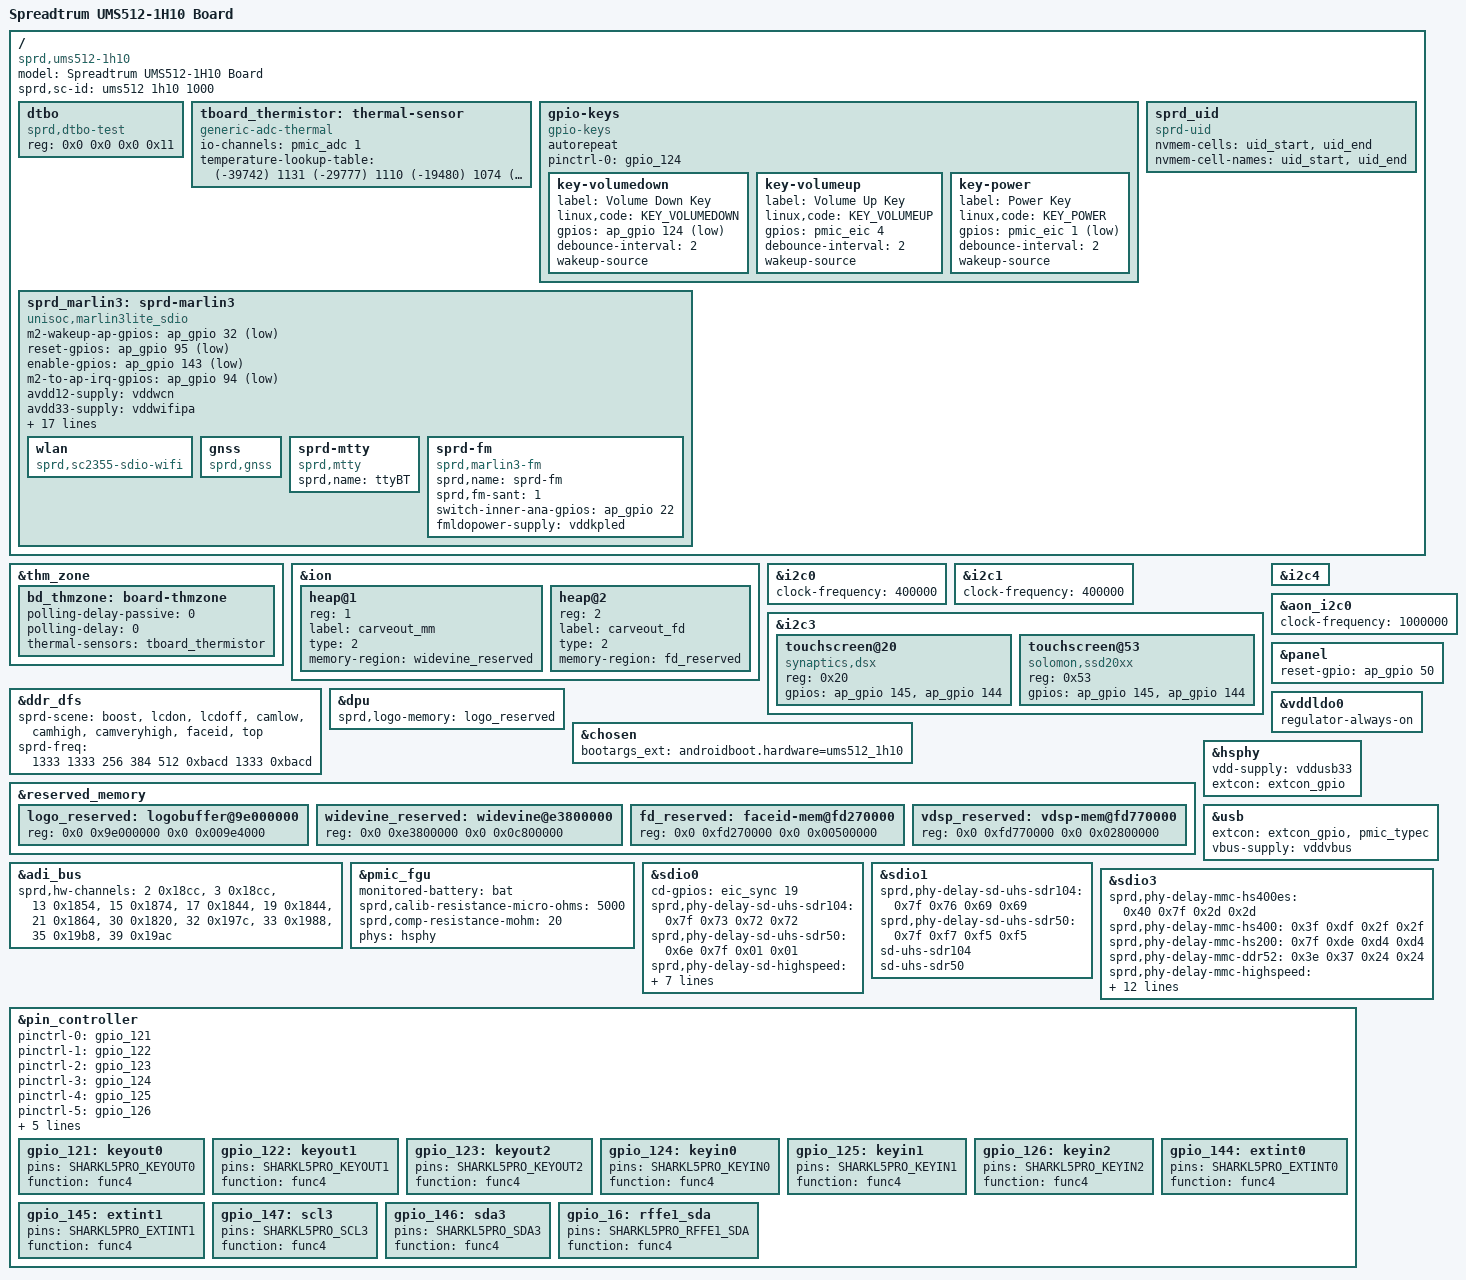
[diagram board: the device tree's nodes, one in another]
/dts-v1/;
/plugin/;

#include <dt-bindings/clock/sprd,ums512-clk.h>
#include <dt-bindings/input/input.h>
#include <dt-bindings/gpio/gpio.h>
#include <dt-bindings/mfd/sprd,sc2730-regs.h>
#include <dt-bindings/mfd/sprd,sc2730-mask.h>



/ {
	model = "Spreadtrum UMS512-1H10 Board";

	compatible = "sprd,ums512-1h10", "sprd,ums512";

	sprd,sc-id = "ums512 1h10 1000";

	fragment {
		target-path = "/";
		__overlay__ {
			#address-cells = <2>;
			#size-cells = <2>;

			dtbo: dtbo {
				compatible = "sprd,dtbo-test";
				reg = <0x0 0x0 0x0 0x11>;
			};
			/*
			pwm_backlight: sprd_backlight {
				compatible = "sprd,sharkl5pro-backlight";
				pwms = <&pwms 2 40000>;
				pwm-names = "backlight";
				sprd,max-brightness-level = <880>;
				default-brightness-level = <250>;
				sprd,brightness-scale = <1023>;
				brightness-levels = <
							  0   3   4   5   6   7
					  8   9  10  11  12  13  14  15  16  17
					 18  19  20  21  22  23  24  25  26  27
					 28  29  31  33  35  37  39  41  43  45
					 46  48  50  52  54  56  58  60  62  64
					 66  68  70  72  74  76  78  80  82  84
					 86  88  90  92  94  96  98 100 102 104
					106 108 110 112 114 116 118 120 122 124
					126 128 130 132 134 136 138 140 142 144
					146 148 150 152 154 156 158 160 162 164
					166 169 172 175 178 181 184 187 190 193
					196 199 202 205 208 211 214 217 220 223
					226 229 232 235 238 241 244 247 250 253
					256 259 262 265 268 271 274 277 280 283
					286 290 294 298 302 306 310 314 318 322
					326 330 334 338 342 346 350 354 358 362
					366 370 374 378 382 386 390 394 398 402
					406 410 414 418 422 426 430 434 438 442
					446 451 456 461 466 471 476 481 486 491
					496 501 506 511 516 521 526 531 536 541
					546 551 556 561 566 571 576 581 586 591
					596 601 606 611 616 621 626 631 636 641
					646 652 658 664 670 676 682 688 694 700
					706 712 718 724 730 736 742 748 754 760
					766 772 778 784 790 796 802 808 814 820
					826 832 838 844 850 856 862 868 874 880
					>;
			};*/


			tboard_thermistor:thermal-sensor {
				compatible = "generic-adc-thermal";
				#thermal-sensor-cells = <0>;
				io-channels = <&pmic_adc 1>;
				io-channel-names = "sensor-channel";
				temperature-lookup-table = <    (-39742) 1131
								(-29777) 1110
								(-19480) 1074
								(-4679) 983
								10110 838
								24805 654
								44922 413
								54903 316
								64895 238
								74884 178
								84883 133
								94883 100
								104880 75
								114889 57
								124872 43 >;
			};
			gpio-keys {
				compatible = "gpio-keys";
				autorepeat;
				pinctrl-names = "gpio_124";
				pinctrl-0 = <&gpio_124>;
				key-volumedown {
					label = "Volume Down Key";
					linux,code = <KEY_VOLUMEDOWN>;
					gpios = <&ap_gpio 124 GPIO_ACTIVE_LOW>;
					debounce-interval = <2>;
					wakeup-source;
				};

				key-volumeup {
					label = "Volume Up Key";
					linux,code = <KEY_VOLUMEUP>;
					gpios = <&pmic_eic 4 GPIO_ACTIVE_HIGH>;
					debounce-interval = <2>;
					wakeup-source;
				};

				key-power {
					label = "Power Key";
					linux,code = <KEY_POWER>;
					gpios = <&pmic_eic 1 GPIO_ACTIVE_LOW>;
					debounce-interval = <2>;
					wakeup-source;
				};
			};

			sprd_uid {
				compatible = "sprd-uid";
				nvmem-cells = <&uid_start>, <&uid_end>;
				nvmem-cell-names = "uid_start", "uid_end";
			};

			sprd_marlin3: sprd-marlin3 {
				compatible = "unisoc,marlin3lite_sdio";
				m2-wakeup-ap-gpios = <&ap_gpio 32 GPIO_ACTIVE_LOW>;
				reset-gpios = <&ap_gpio 95 GPIO_ACTIVE_LOW>;
				enable-gpios = <&ap_gpio 143 GPIO_ACTIVE_LOW>;
				m2-to-ap-irq-gpios = <&ap_gpio 94 GPIO_ACTIVE_LOW>;
				avdd12-supply = <&vddwcn>;
				avdd33-supply = <&vddwifipa>;
				dcxo18-supply = <&vddsim2>;

				clock-names = "clk_32k","source","enable";
				clocks = <&aon_clk CLK_AUX0>,
					 <&ext_32k>,
					 <&aonapb_gate CLK_AUX0_EB>;

				extcon = <&sdio1>;
				sdhci-name = <&sdio1>;

				sprd,btwf-file-name = "/dev/block/platform/soc/soc:ap-apb/71400000.sdio/by-name/wcnmodem";
				sprd,gnss-file-name = "/vendor/firmware/gnssmodem.bin";
				adma-tx;
				adma-rx;
				/*
				 * bound parameter:
				 * [0]:addr offset, [1]:mask, [2]:unboundval, [3]:boundval
				 */
				avdd12-parent-bound-chip = <REG_ANA_SLP_DCDC_PD_CTRL MASK_ANA_SLP_DCDCGEN1_PD_EN 0x0 MASK_ANA_SLP_DCDCGEN1_PD_EN>;
				avdd12-bound-wbreq = <REG_ANA_LDO_XTL_EN10 MASK_ANA_LDO_VDDWCN_EXT_XTL3_EN 0x0 MASK_ANA_LDO_VDDWCN_EXT_XTL3_EN>;
				avdd33-bound-wbreq = <REG_ANA_LDO_XTL_EN11 MASK_ANA_LDO_VDDWIFIPA_EXT_XTL3_EN 0x0 MASK_ANA_LDO_VDDWIFIPA_EXT_XTL3_EN>;

				wlan {
					compatible = "sprd,sc2355-sdio-wifi";
				};

				gnss {
					compatible = "sprd,gnss";
				};

				sprd-mtty {
					compatible = "sprd,mtty";
					sprd,name = "ttyBT";
				};

				sprd-fm {
					compatible = "sprd,marlin3-fm";
					sprd,name = "sprd-fm";
					sprd,fm-sant = <1>;
					switch-inner-ana-gpios = <&ap_gpio 22 0>; /*support lna switch */
					fmldopower-supply = <&vddkpled>;
				};
			};
		};
	};
};

&thm_zone {
	bd_thmzone: board-thmzone {
		polling-delay-passive = <0>;
		polling-delay = <0>;
		thermal-sensors = <&tboard_thermistor>;
	};
};

&ion {
	#address-cells = <1>;
	#size-cells = <0>;

	heap@1 {
		reg = <1>;
		label = "carveout_mm";
		type = <2>;
		memory-region = <&widevine_reserved>;
	};

	heap@2 {
		reg = <2>;
		label = "carveout_fd";
		type = <2>;
		memory-region = <&fd_reserved>;
	};
};

&i2c0 {
	#address-cells = <1>;
	#size-cells = <0>;

	status = "okay";
	clock-frequency = <400000>;

};

&i2c1 {
	#address-cells = <1>;
	#size-cells = <0>;

	status = "okay";
	clock-frequency = <400000>;
};

&i2c3 {
	#address-cells = <1>;
	#size-cells = <0>;

	status = "okay";

	touchscreen@20 {
		compatible = "synaptics,dsx";
		reg = <0x20>;
		gpios = <&ap_gpio 145 GPIO_ACTIVE_HIGH>,
			<&ap_gpio 144 GPIO_ACTIVE_HIGH>;
	};

	touchscreen@53 {
		compatible = "solomon,ssd20xx";
		reg = <0x53>;
		gpios = <&ap_gpio 145 GPIO_ACTIVE_HIGH>,
			<&ap_gpio 144 GPIO_ACTIVE_HIGH>;
	};

};

&i2c4 {
	#address-cells = <1>;
	#size-cells = <0>;


};

&aon_i2c0 {
	status = "okay";
	clock-frequency = <1000000>;
};

&ddr_dfs {
	sprd-scene = "boost", "lcdon", "lcdoff", "camlow",
		"camhigh", "camveryhigh", "faceid", "top";
	sprd-freq = <1333 1333 256 384 512 0xbacd 1333 0xbacd>;
};

&panel {
	/*sprd,backlight = <&pwm_backlight>;*/
	reset-gpio = <&ap_gpio 50 GPIO_ACTIVE_HIGH>;
};

&dpu {
	/*sprd,backlight = <&pwm_backlight>;*/
	sprd,logo-memory = <&logo_reserved>;
};

&chosen {
	bootargs_ext = "androidboot.hardware=ums512_1h10";
};

&reserved_memory {
	#address-cells = <2>;
	#size-cells = <2>;

	logo_reserved: logobuffer@9e000000{
		reg = <0x0 0x9e000000 0x0 0x009e4000>;
	};

	widevine_reserved: widevine@e3800000 {
		reg = <0x0 0xe3800000 0x0 0x0c800000>;
	};

	fd_reserved: faceid-mem@fd270000 {
		reg = <0x0 0xfd270000 0x0 0x00500000>;
	};

	vdsp_reserved: vdsp-mem@fd770000 {
		reg = <0x0 0xfd770000 0x0 0x02800000>;
	};
};

&adi_bus {
	sprd,hw-channels = <2 0x18cc>, <3 0x18cc>, <13 0x1854>, <15 0x1874>,
			   <17 0x1844>, <19 0x1844>, <21 0x1864>, <30 0x1820>,
			   <32 0x197c>, <33 0x1988>, <35 0x19b8>, <39 0x19ac>;
};

&vddldo0 {
	regulator-always-on;
};

&hsphy {
	vdd-supply = <&vddusb33>;
	extcon = <&extcon_gpio>;
	status = "okay";
};

&usb {
	extcon = <&extcon_gpio>, <&pmic_typec>;
	status = "okay";
	vbus-supply = <&vddvbus>;
};

&pmic_fgu {
	monitored-battery = <&bat>;
	sprd,calib-resistance-micro-ohms = <5000>;
	sprd,comp-resistance-mohm = <20>;

	/*fgu-capacity-track;*/

	phys = <&hsphy>;
};

&sdio0 {
	cd-gpios = <&eic_sync 19 GPIO_ACTIVE_HIGH>;
	sprd,phy-delay-sd-uhs-sdr104 = <0x7f 0x73 0x72 0x72>;
	sprd,phy-delay-sd-uhs-sdr50 = <0x6e 0x7f 0x01 0x01>;
	sprd,phy-delay-sd-highspeed = <0x7f 0x1a 0x9a 0x9a>;
	sprd,phy-delay-legacy = <0x7f 0x1a 0x9a 0x9a>;
	vmmc-supply = <&vddsdcore>;
	vqmmc-supply = <&vddsdio>;
	sd-uhs-sdr104;
	sd-uhs-sdr50;
	sprd,name = "sdio_sd";
	status = "okay";
};

&sdio1 {
	sprd,phy-delay-sd-uhs-sdr104 = <0x7f 0x76 0x69 0x69>;
	sprd,phy-delay-sd-uhs-sdr50 = <0x7f 0xf7 0xf5 0xf5>;
	sd-uhs-sdr104;
	sd-uhs-sdr50;
};

&sdio3 {
	sprd,phy-delay-mmc-hs400es = <0x40 0x7f 0x2d 0x2d>;
	sprd,phy-delay-mmc-hs400 = <0x3f 0xdf 0x2f 0x2f>;
	sprd,phy-delay-mmc-hs200 = <0x7f 0xde 0xd4 0xd4>;
	sprd,phy-delay-mmc-ddr52 = <0x3e 0x37 0x24 0x24>;
	sprd,phy-delay-mmc-highspeed = <0x7f 0xa1 0xa1 0xa1>;
	vmmc-supply = <&vddemmccore>;
	voltage-ranges = <3000 3000>;
	bus-width = <8>;
	non-removable;
	cap-mmc-hw-reset;
	mmc-hs400-enhanced-strobe;
	mmc-hs400-1_8v;
	mmc-hs200-1_8v;
	mmc-ddr-1_8v;
	no-sdio;
	no-sd;
	status = "okay";
};

&pin_controller {
	pinctrl-names =
	/* keyout0 ~ keyout2 */
	"gpio_121", "gpio_122", "gpio_123",
	/* keyin0 ~ keyin2 */
	"gpio_124", "gpio_125", "gpio_126",
	/* extint0, extint1, scl3, sda3, sda */
	"gpio_144", "gpio_145", "gpio_146", "gpio_147", "gpio_16";

	pinctrl-0 = <&gpio_121>;
	pinctrl-1 = <&gpio_122>;
	pinctrl-2 = <&gpio_123>;
	pinctrl-3 = <&gpio_124>;
	pinctrl-4 = <&gpio_125>;
	pinctrl-5 = <&gpio_126>;
	pinctrl-6 = <&gpio_144>;
	pinctrl-7 = <&gpio_145>;
	pinctrl-8 = <&gpio_146>;
	pinctrl-9 = <&gpio_147>;
	pinctrl-10 = <&gpio_16>;

	gpio_121: keyout0 {
		pins = "SHARKL5PRO_KEYOUT0";
		function = "func4";
	};

	gpio_122: keyout1 {
		pins = "SHARKL5PRO_KEYOUT1";
		function = "func4";
	};

	gpio_123: keyout2 {
		pins = "SHARKL5PRO_KEYOUT2";
		function = "func4";
	};

	gpio_124: keyin0 {
		pins = "SHARKL5PRO_KEYIN0";
		function = "func4";
	};

	gpio_125: keyin1 {
		pins = "SHARKL5PRO_KEYIN1";
		function = "func4";
	};

	gpio_126: keyin2 {
		pins = "SHARKL5PRO_KEYIN2";
		function = "func4";
	};

	gpio_144: extint0 {
		pins = "SHARKL5PRO_EXTINT0";
		function = "func4";
	};

	gpio_145: extint1 {
		pins = "SHARKL5PRO_EXTINT1";
		function = "func4";
	};

	gpio_147: scl3 {
		pins = "SHARKL5PRO_SCL3";
		function = "func4";
	};

	gpio_146: sda3 {
		pins = "SHARKL5PRO_SDA3";
		function = "func4";
	};

	gpio_16: rffe1_sda {
		pins = "SHARKL5PRO_RFFE1_SDA";
		function = "func4";
	};
};

